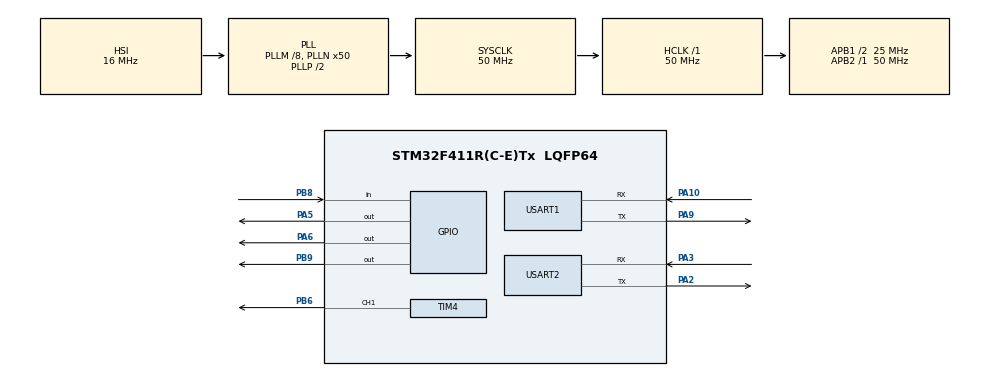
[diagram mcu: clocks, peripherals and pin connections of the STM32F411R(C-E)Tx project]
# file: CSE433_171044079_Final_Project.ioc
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Mcu.Family=STM32F4
Mcu.Name=STM32F411R(C-E)Tx
Mcu.Package=LQFP64
NVIC.PriorityGroup=NVIC_PRIORITYGROUP_4
NVIC.TIM4_IRQn=true\:0\:0\:false\:false\:true\:true\:true
NVIC.USART1_IRQn=true\:0\:0\:false\:false\:true\:true\:true
NVIC.USART2_IRQn=true\:0\:0\:false\:false\:true\:true\:true
PA10.Mode=Asynchronous
PA10.Signal=USART1_RX
PA2.Mode=Asynchronous
PA2.Signal=USART2_TX
PA3.Mode=Asynchronous
PA3.Signal=USART2_RX
PA5.Signal=GPIO_Output
PA6.Signal=GPIO_Output
PA9.Mode=Asynchronous
PA9.Signal=USART1_TX
PB6.Signal=S_TIM4_CH1
PB8.Signal=GPIO_Input
PB9.Signal=GPIO_Output
ProjectManager.HeapSize=0x200
ProjectManager.StackSize=0x400
ProjectManager.TargetToolchain=STM32CubeIDE
RCC.48MHZClocksFreq_Value=25000000
RCC.AHBFreq_Value=50000000
RCC.APB1CLKDivider=RCC_HCLK_DIV2
RCC.APB1Freq_Value=25000000
RCC.APB1TimFreq_Value=50000000
RCC.APB2Freq_Value=50000000
RCC.APB2TimFreq_Value=50000000
RCC.CortexFreq_Value=50000000
RCC.HCLKFreq_Value=50000000
RCC.HSE_VALUE=25000000
RCC.HSI_VALUE=16000000
RCC.LSE_VALUE=32768
RCC.PLLM=8
RCC.PLLN=50
RCC.SYSCLKFreq_VALUE=50000000
RCC.SYSCLKSource=RCC_SYSCLKSOURCE_PLLCLK
RCC.VCOOutputFreq_Value=100000000
SH.S_TIM4_CH1.0=TIM4_CH1,PWM Generation1 CH1
TIM3.Period=0xffff - 1
TIM3.Prescaler=50-1
TIM4.Channel-PWM\ Generation1\ CH1=TIM_CHANNEL_1
TIM4.Period=1000-1
TIM4.Prescaler=1000-1
USART1.VirtualMode=VM_ASYNC
USART2.VirtualMode=VM_ASYNC
VP_TIM3_VS_ClockSourceINT.Mode=Internal
VP_TIM4_VS_ClockSourceINT.Mode=Internal
board=custom

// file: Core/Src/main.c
/* USER CODE BEGIN Header */
/**
  ******************************************************************************
  * @file           : main.c
  * @brief          : Main program body
  ******************************************************************************
  * @attention
  *
  * <h2><center>&copy; Copyright (c) 2020 STMicroelectronics.
  * All rights reserved.</center></h2>
  *
  * This software component is licensed by ST under BSD 3-Clause license,
  * the "License"; You may not use this file except in compliance with the
  * License. You may obtain a copy of the License at:
  *                        opensource.org/licenses/BSD-3-Clause
  *
  ******************************************************************************
  */
/* USER CODE END Header */

#include "main.h"

/* USER CODE BEGIN Includes */
#include "ESP8266_HAL.h"
#include "HX711.h"
#include "stdio.h"
/* USER CODE END Includes */

TIM_HandleTypeDef htim3;
TIM_HandleTypeDef htim4;

UART_HandleTypeDef huart1;
UART_HandleTypeDef huart2;

/* USER CODE BEGIN PV */
hx711_t hx711;

/* USER CODE END PV */

void SystemClock_Config(void);
static void MX_GPIO_Init(void);
static void MX_TIM3_Init(void);
static void MX_TIM4_Init(void);
static void MX_USART1_UART_Init(void);
static void MX_USART2_UART_Init(void);

int main(void)
{

  /* MCU Configuration--------------------------------------------------------*/

  /* Reset of all peripherals, Initializes the Flash interface and the Systick. */
  HAL_Init();

  /* Configure the system clock */
  SystemClock_Config();

  /* Initialize all configured peripherals */
  MX_GPIO_Init();
  MX_TIM3_Init();
  MX_TIM4_Init();
  MX_USART1_UART_Init();
  MX_USART2_UART_Init();
  /* USER CODE BEGIN 2 */
  HAL_TIM_PWM_Start(&htim4,TIM_CHANNEL_1);
  HAL_TIM_Base_Start(&htim3);

  Ringbuf_init();
  init_hx711_port(&hx711, GPIOB, GPIO_PIN_9, GPIOB, GPIO_PIN_8);

  ESP_Init("A8_9_SUPERONLINE_2","mamikyasir6142");

  /* USER CODE END 2 */

  /* Infinite loop */
  while (1)
  {

    /* USER CODE BEGIN 3 */
	  Server_Start();

  }
  /* USER CODE END 3 */
}

void SystemClock_Config(void)
{
  RCC_OscInitTypeDef RCC_OscInitStruct = {0};
  RCC_ClkInitTypeDef RCC_ClkInitStruct = {0};

  /** Configure the main internal regulator output voltage
  */
  __HAL_RCC_PWR_CLK_ENABLE();
  __HAL_PWR_VOLTAGESCALING_CONFIG(PWR_REGULATOR_VOLTAGE_SCALE1);
  /** Initializes the CPU, AHB and APB busses clocks
  */
  RCC_OscInitStruct.OscillatorType = RCC_OSCILLATORTYPE_HSI;
  RCC_OscInitStruct.HSIState = RCC_HSI_ON;
  RCC_OscInitStruct.HSICalibrationValue = RCC_HSICALIBRATION_DEFAULT;
  RCC_OscInitStruct.PLL.PLLState = RCC_PLL_ON;
  RCC_OscInitStruct.PLL.PLLSource = RCC_PLLSOURCE_HSI;
  RCC_OscInitStruct.PLL.PLLM = 8;
  RCC_OscInitStruct.PLL.PLLN = 50;
  RCC_OscInitStruct.PLL.PLLP = RCC_PLLP_DIV2;
  RCC_OscInitStruct.PLL.PLLQ = 4;
  if (HAL_RCC_OscConfig(&RCC_OscInitStruct) != HAL_OK)
  {
    Error_Handler();
  }
  /** Initializes the CPU, AHB and APB busses clocks
  */
  RCC_ClkInitStruct.ClockType = RCC_CLOCKTYPE_HCLK|RCC_CLOCKTYPE_SYSCLK
                              |RCC_CLOCKTYPE_PCLK1|RCC_CLOCKTYPE_PCLK2;
  RCC_ClkInitStruct.SYSCLKSource = RCC_SYSCLKSOURCE_PLLCLK;
  RCC_ClkInitStruct.AHBCLKDivider = RCC_SYSCLK_DIV1;
  RCC_ClkInitStruct.APB1CLKDivider = RCC_HCLK_DIV2;
  RCC_ClkInitStruct.APB2CLKDivider = RCC_HCLK_DIV1;

  if (HAL_RCC_ClockConfig(&RCC_ClkInitStruct, FLASH_LATENCY_1) != HAL_OK)
  {
    Error_Handler();
  }
}

static void MX_TIM3_Init(void)
{

  TIM_ClockConfigTypeDef sClockSourceConfig = {0};
  TIM_MasterConfigTypeDef sMasterConfig = {0};

  htim3.Instance = TIM3;
  htim3.Init.Prescaler = 50-1;
  htim3.Init.CounterMode = TIM_COUNTERMODE_UP;
  htim3.Init.Period = 0xffff - 1;
  htim3.Init.ClockDivision = TIM_CLOCKDIVISION_DIV1;
  htim3.Init.AutoReloadPreload = TIM_AUTORELOAD_PRELOAD_DISABLE;
  if (HAL_TIM_Base_Init(&htim3) != HAL_OK)
  {
    Error_Handler();
  }
  sClockSourceConfig.ClockSource = TIM_CLOCKSOURCE_INTERNAL;
  if (HAL_TIM_ConfigClockSource(&htim3, &sClockSourceConfig) != HAL_OK)
  {
    Error_Handler();
  }
  sMasterConfig.MasterOutputTrigger = TIM_TRGO_RESET;
  sMasterConfig.MasterSlaveMode = TIM_MASTERSLAVEMODE_DISABLE;
  if (HAL_TIMEx_MasterConfigSynchronization(&htim3, &sMasterConfig) != HAL_OK)
  {
    Error_Handler();
  }

}

static void MX_TIM4_Init(void)
{

  TIM_ClockConfigTypeDef sClockSourceConfig = {0};
  TIM_MasterConfigTypeDef sMasterConfig = {0};
  TIM_OC_InitTypeDef sConfigOC = {0};

  htim4.Instance = TIM4;
  htim4.Init.Prescaler = 1000-1;
  htim4.Init.CounterMode = TIM_COUNTERMODE_UP;
  htim4.Init.Period = 1000-1;
  htim4.Init.ClockDivision = TIM_CLOCKDIVISION_DIV1;
  htim4.Init.AutoReloadPreload = TIM_AUTORELOAD_PRELOAD_DISABLE;
  if (HAL_TIM_Base_Init(&htim4) != HAL_OK)
  {
    Error_Handler();
  }
  sClockSourceConfig.ClockSource = TIM_CLOCKSOURCE_INTERNAL;
  if (HAL_TIM_ConfigClockSource(&htim4, &sClockSourceConfig) != HAL_OK)
  {
    Error_Handler();
  }
  if (HAL_TIM_PWM_Init(&htim4) != HAL_OK)
  {
    Error_Handler();
  }
  sMasterConfig.MasterOutputTrigger = TIM_TRGO_RESET;
  sMasterConfig.MasterSlaveMode = TIM_MASTERSLAVEMODE_DISABLE;
  if (HAL_TIMEx_MasterConfigSynchronization(&htim4, &sMasterConfig) != HAL_OK)
  {
    Error_Handler();
  }
  sConfigOC.OCMode = TIM_OCMODE_PWM1;
  sConfigOC.Pulse = 0;
  sConfigOC.OCPolarity = TIM_OCPOLARITY_HIGH;
  sConfigOC.OCFastMode = TIM_OCFAST_DISABLE;
  if (HAL_TIM_PWM_ConfigChannel(&htim4, &sConfigOC, TIM_CHANNEL_1) != HAL_OK)
  {
    Error_Handler();
  }
  HAL_TIM_MspPostInit(&htim4);

}

static void MX_USART1_UART_Init(void)
{

  huart1.Instance = USART1;
  huart1.Init.BaudRate = 115200;
  huart1.Init.WordLength = UART_WORDLENGTH_8B;
  huart1.Init.StopBits = UART_STOPBITS_1;
  huart1.Init.Parity = UART_PARITY_NONE;
  huart1.Init.Mode = UART_MODE_TX_RX;
  huart1.Init.HwFlowCtl = UART_HWCONTROL_NONE;
  huart1.Init.OverSampling = UART_OVERSAMPLING_16;
  if (HAL_UART_Init(&huart1) != HAL_OK)
  {
    Error_Handler();
  }

}

static void MX_USART2_UART_Init(void)
{

  huart2.Instance = USART2;
  huart2.Init.BaudRate = 115200;
  huart2.Init.WordLength = UART_WORDLENGTH_8B;
  huart2.Init.StopBits = UART_STOPBITS_1;
  huart2.Init.Parity = UART_PARITY_NONE;
  huart2.Init.Mode = UART_MODE_TX_RX;
  huart2.Init.HwFlowCtl = UART_HWCONTROL_NONE;
  huart2.Init.OverSampling = UART_OVERSAMPLING_16;
  if (HAL_UART_Init(&huart2) != HAL_OK)
  {
    Error_Handler();
  }

}

static void MX_GPIO_Init(void)
{
  GPIO_InitTypeDef GPIO_InitStruct = {0};

  /* GPIO Ports Clock Enable */
  __HAL_RCC_GPIOA_CLK_ENABLE();
  __HAL_RCC_GPIOB_CLK_ENABLE();

  /*Configure GPIO pin Output Level */
  HAL_GPIO_WritePin(GPIOA, GPIO_PIN_5|GPIO_PIN_6, GPIO_PIN_RESET);

  /*Configure GPIO pin Output Level */
  HAL_GPIO_WritePin(GPIOB, GPIO_PIN_9, GPIO_PIN_RESET);

  /*Configure GPIO pins : PA5 PA6 */
  GPIO_InitStruct.Pin = GPIO_PIN_5|GPIO_PIN_6;
  GPIO_InitStruct.Mode = GPIO_MODE_OUTPUT_PP;
  GPIO_InitStruct.Pull = GPIO_NOPULL;
  GPIO_InitStruct.Speed = GPIO_SPEED_FREQ_LOW;
  HAL_GPIO_Init(GPIOA, &GPIO_InitStruct);

  /*Configure GPIO pin : PB8 */
  GPIO_InitStruct.Pin = GPIO_PIN_8;
  GPIO_InitStruct.Mode = GPIO_MODE_INPUT;
  GPIO_InitStruct.Pull = GPIO_NOPULL;
  HAL_GPIO_Init(GPIOB, &GPIO_InitStruct);

  /*Configure GPIO pin : PB9 */
  GPIO_InitStruct.Pin = GPIO_PIN_9;
  GPIO_InitStruct.Mode = GPIO_MODE_OUTPUT_PP;
  GPIO_InitStruct.Pull = GPIO_NOPULL;
  GPIO_InitStruct.Speed = GPIO_SPEED_FREQ_LOW;
  HAL_GPIO_Init(GPIOB, &GPIO_InitStruct);

}

void Error_Handler(void)
{
}

/************************ (C) COPYRIGHT STMicroelectronics *****END OF FILE****/
